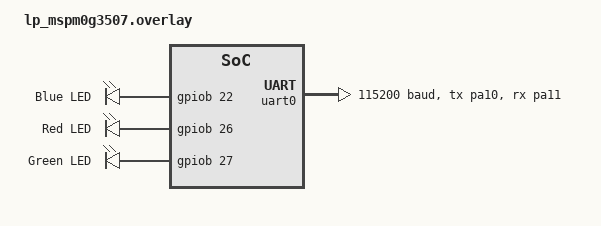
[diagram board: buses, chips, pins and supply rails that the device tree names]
/ {
	aliases {
		led1 = &led1;
		led2 = &led2;
  	};

	chosen {
		zephyr,console = &uart0;
		zephyr,shell-uart = &uart0;
		zephyr,uart-mcumgr = &uart0;
		zephyr,code-partition = &slot0_partition;
		zephyr,flash-controller = &flashctl;
	};

	leds {
		compatible = "gpio-leds";

		led0: led_0 {
			gpios = <&gpiob 22 GPIO_ACTIVE_HIGH>;
			label = "Blue LED";
		};
		
		led1: led_1 {
			gpios = <&gpiob 26 GPIO_ACTIVE_HIGH>;
			label = "Red LED";
		};

		led2: led_2 {
			gpios = <&gpiob 27 GPIO_ACTIVE_HIGH>;
			label = "Green LED";
		};
	};
};

&uart0 {
	current-speed = <115200>;
	clocks = <&ckm MSPM0_CLOCK_ULPCLK>;
	pinctrl-0 = <&uart0_tx_pa10 &uart0_rx_pa11>;
    status = "okay";
};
